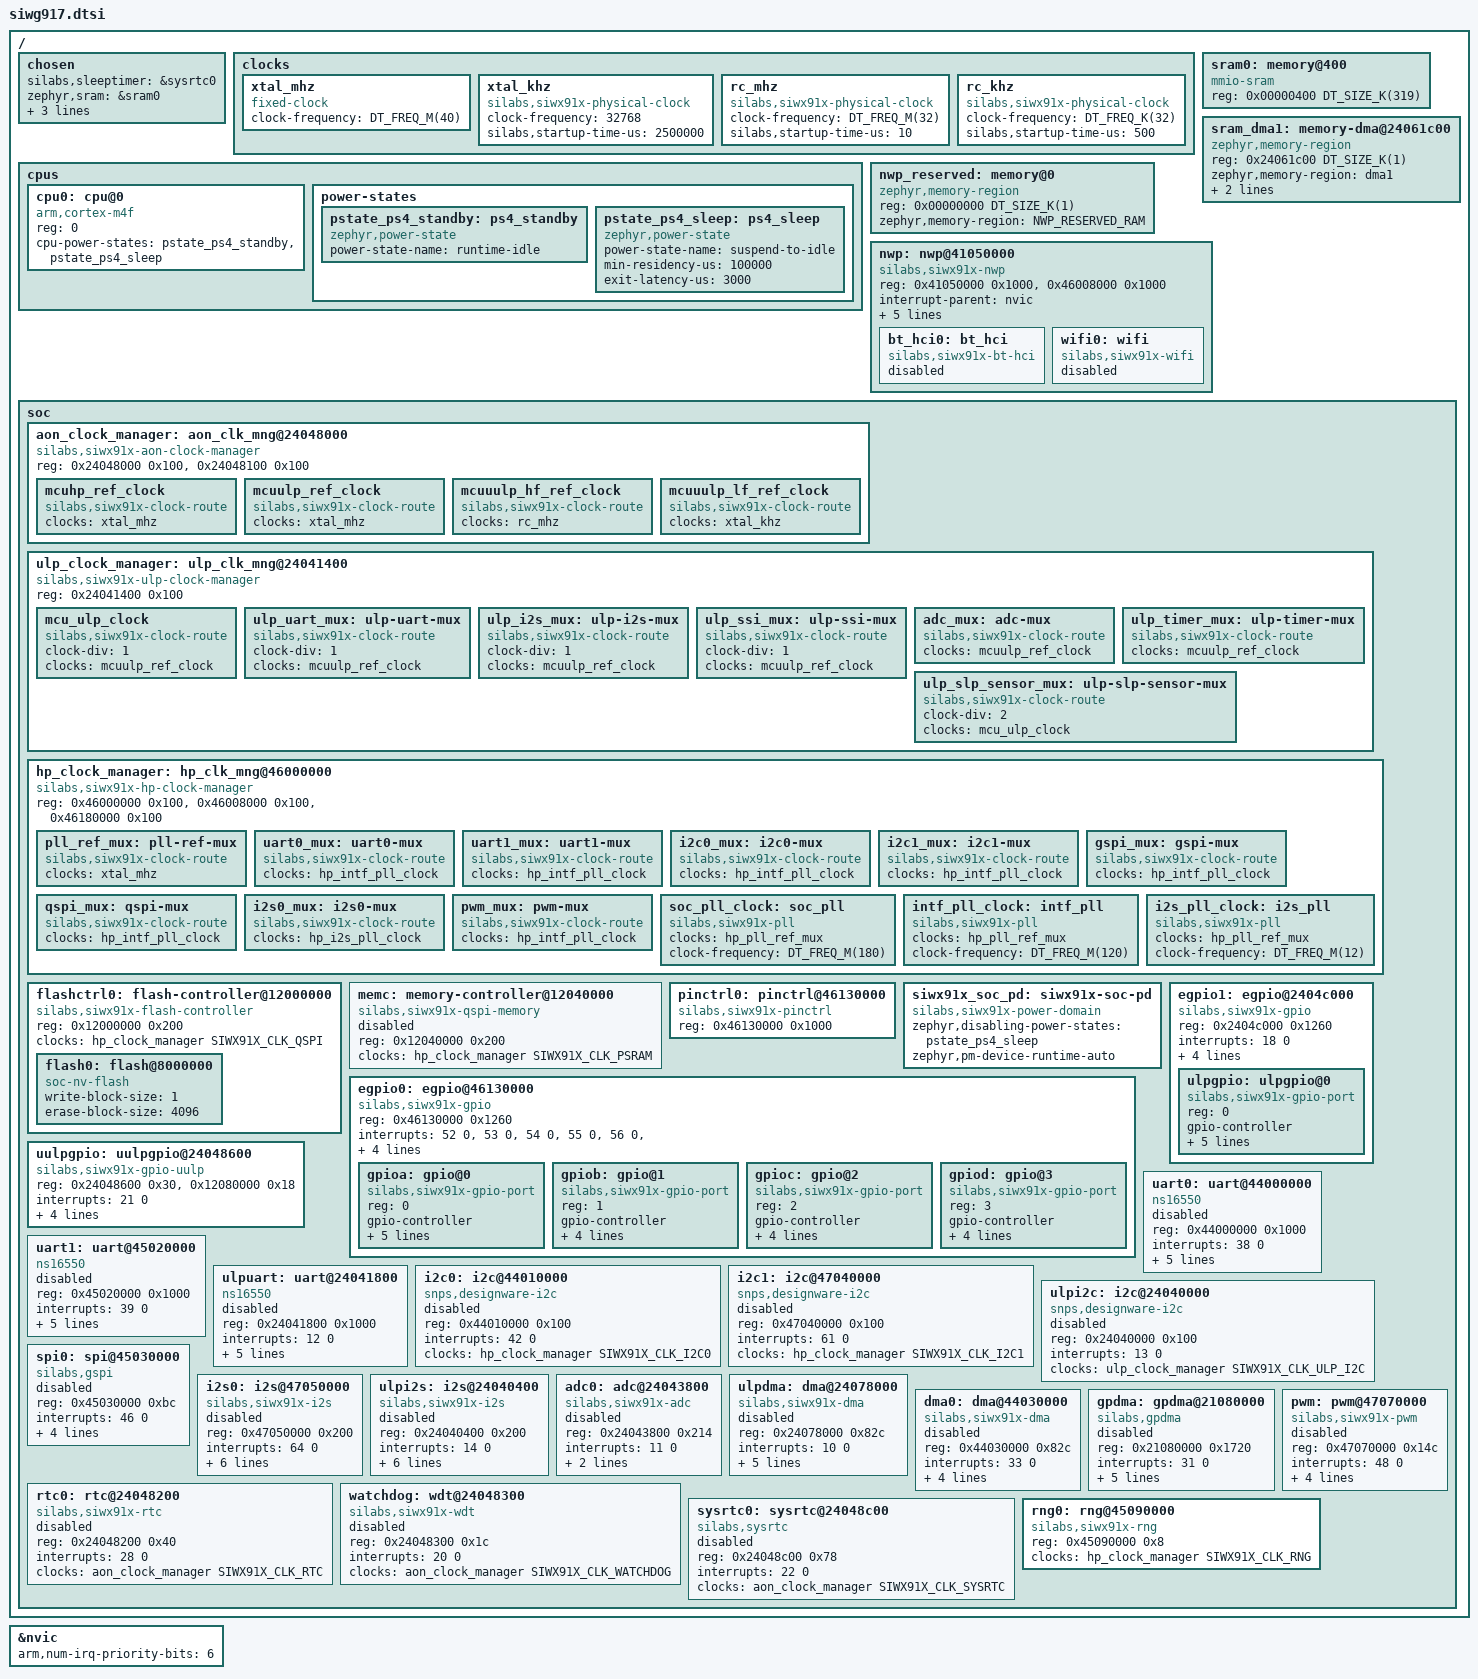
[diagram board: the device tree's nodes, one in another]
/*
 * Copyright (c) 2024-2025 Silicon Laboratories Inc.
 *
 * SPDX-License-Identifier: Apache-2.0
 */

#include <arm/armv7-m.dtsi>
#include <zephyr/dt-bindings/clock/silabs/siwx91x-clock.h>
#include <zephyr/dt-bindings/memory-attr/memory-attr-arm.h>
#include <freq.h>

/ {
	chosen {
		silabs,sleeptimer = &sysrtc0;
		zephyr,sram = &sram0;
		zephyr,entropy = &rng0;
		zephyr,flash = &flash0;
		zephyr,flash-controller = &flashctrl0;
	};

	clocks {

		xtal_mhz: xtal_mhz {
			compatible = "fixed-clock";
			#clock-cells = <0>;
			clock-frequency = <DT_FREQ_M(40)>;
			status = "okay";
		};

		xtal_khz: xtal_khz {
			compatible = "silabs,siwx91x-physical-clock";
			#clock-cells = <0>;
			clock-frequency = <32768>;
			silabs,startup-time-us = <2500000>;
			status = "okay";
		};

		rc_mhz: rc_mhz {
			compatible = "silabs,siwx91x-physical-clock";
			#clock-cells = <0>;
			clock-frequency = <DT_FREQ_M(32)>;
			silabs,startup-time-us = <10>;
			status = "okay";
		};

		rc_khz: rc_khz {
			compatible = "silabs,siwx91x-physical-clock";
			#clock-cells = <0>;
			clock-frequency = <DT_FREQ_K(32)>;
			silabs,startup-time-us = <500>;
			status = "okay";
		};

	};

	cpus {
		#address-cells = <1>;
		#size-cells = <0>;

		cpu0: cpu@0 {
			compatible = "arm,cortex-m4f";
			reg = <0>;
			cpu-power-states = <&pstate_ps4_standby &pstate_ps4_sleep>;
		};

		power-states {
			pstate_ps4_standby: ps4_standby {
				compatible = "zephyr,power-state";
				power-state-name = "runtime-idle";
			};

			pstate_ps4_sleep: ps4_sleep {
				compatible = "zephyr,power-state";
				power-state-name = "suspend-to-idle";
				min-residency-us = <100000>;
				exit-latency-us = <3000>;
			};
		};
	};

	/* First 1KB of SRAM reserved for NWP (protects against null pointers) */
	nwp_reserved: memory@0 {
		compatible = "zephyr,memory-region", "mmio-sram";
		reg = <0x00000000 DT_SIZE_K(1)>;
		zephyr,memory-region = "NWP_RESERVED_RAM";
	};

	/* Main SRAM for Cortex-M4 (shared with NWP)
	 * Configurable: 195KB, 255KB, or 319KB
	 * More to M4 = less to NWP (but better wireless performance)
	 */
	sram0: memory@400 {
		compatible = "mmio-sram";
		reg = <0x00000400 DT_SIZE_K(319)>;
	};

	/* DMA SRAM - No-cache memory for DMA transfers */
	sram_dma1: memory-dma@24061c00 {
		compatible = "zephyr,memory-region", "mmio-sram";
		reg = <0x24061c00 DT_SIZE_K(1)>;
		zephyr,memory-region = "dma1";
		zephyr,memory-attr = <DT_MEM_ARM(ATTR_MPU_RAM_NOCACHE)>;
	};

	nwp: nwp@41050000 {
		compatible = "silabs,siwx91x-nwp";
		reg = <0x41050000 0x1000>, <0x46008000 0x1000>;
		reg-names = "ta", "m4";
		interrupt-parent = <&nvic>;
		interrupts = <74 0>;
		interrupt-names = "nwp_irq";
		antenna-selection = "internal";
		support-1p8v;
		enable-xtal-correction;
		clock-frequency = <DT_FREQ_M(80)>;
		status = "okay";

		bt_hci0: bt_hci {
			compatible = "silabs,siwx91x-bt-hci";
			status = "disabled";
		};

		wifi0: wifi {
			compatible = "silabs,siwx91x-wifi";
			status = "disabled";
		};
	};

	soc {
		aon_clock_manager: aon_clk_mng@24048000 {
			compatible = "silabs,siwx91x-aon-clock-manager";
			reg = <0x24048000 0x100>,
			      <0x24048100 0x100>;

			reg-names = "mcu_aon","mcu_fsm";
			#clock-cells = <1>;
			status = "okay";

			mcuhp_ref_clock: mcuhp_ref_clock {
				compatible = "silabs,siwx91x-clock-route";
				#clock-cells = <0>;
				clocks = <&xtal_mhz>;
			};

			mcuulp_ref_clock: mcuulp_ref_clock {
				compatible = "silabs,siwx91x-clock-route";
				#clock-cells = <0>;
				clocks = <&xtal_mhz>;
			};

			/* Low-Power State machines clock */
			mcuuulp_hf_ref_clock: mcuuulp_hf_ref_clock {
				compatible = "silabs,siwx91x-clock-route";
				#clock-cells = <0>;
				clocks = <&rc_mhz>;
			};

			/* Shared clock for watchdog/Deep-sleep timer and GPIO timestamping in the UULP domain */
			mcuuulp_lf_ref_clock: mcuuulp_lf_ref_clock {
				compatible = "silabs,siwx91x-clock-route";
				#clock-cells = <0>;
				clocks = <&xtal_khz>;
			};

			/* RTC and watchdog LF muxes are fixed to UULP LF ref in hardware. */
			/* SYSRTC source: sleeptimer / HAL, not a clock-route child here. */
		};

		ulp_clock_manager: ulp_clk_mng@24041400 {
			compatible = "silabs,siwx91x-ulp-clock-manager";
			reg = <0x24041400 0x100>;
			reg-names = "ulpclk";
			#clock-cells = <1>;
			status = "okay";

			/* ULP AHB / processor interface clock (not owned by a single peripheral). */
			mcu_ulp_clock: mcu_ulp_clock {
				compatible = "silabs,siwx91x-clock-route";
				#clock-cells = <0>;
				clock-div = <1>;
				clocks = <&mcuulp_ref_clock>;
			};

			ulp_uart_mux: ulp-uart-mux {
				compatible = "silabs,siwx91x-clock-route";
				#clock-cells = <0>;
				clock-div = <1>;
				clocks = <&mcuulp_ref_clock>;
			};


			ulp_i2s_mux: ulp-i2s-mux {
				compatible = "silabs,siwx91x-clock-route";
				#clock-cells = <0>;
				clock-div = <1>;
				clocks = <&mcuulp_ref_clock>;
			};

			ulp_ssi_mux: ulp-ssi-mux {
				compatible = "silabs,siwx91x-clock-route";
				#clock-cells = <0>;
				clock-div = <1>;
				clocks = <&mcuulp_ref_clock>;
			};

			adc_mux: adc-mux {
				compatible = "silabs,siwx91x-clock-route";
				#clock-cells = <0>;
				clocks = <&mcuulp_ref_clock>;
			};

			ulp_timer_mux: ulp-timer-mux {
				compatible = "silabs,siwx91x-clock-route";
				#clock-cells = <0>;
				clocks = <&mcuulp_ref_clock>;
			};

			/* Sleep sensor clock - APB bus clock to configure uulp peripheral clocks */
			ulp_slp_sensor_mux: ulp-slp-sensor-mux {
				compatible = "silabs,siwx91x-clock-route";
				#clock-cells = <0>;
				clock-div = <2>;
				clocks = <&mcu_ulp_clock>;
			};

		};

		hp_clock_manager: hp_clk_mng@46000000 {
			compatible = "silabs,siwx91x-hp-clock-manager";
			reg = <0x46000000 0x100>,
			      <0x46008000 0x100>,
			      <0x46180000 0x100>;
			reg-names = "m4clk", "misc_config", "pll";
			#clock-cells = <1>;
			status = "okay";

			/* Shared PLL reference mux (one source for SoC/INTF/I2S PLLs). */
			pll_ref_mux: pll-ref-mux {
				compatible = "silabs,siwx91x-clock-route";
				#clock-cells = <0>;
				clocks = <&xtal_mhz>;
			};

			uart0_mux: uart0-mux {
				compatible = "silabs,siwx91x-clock-route";
				#clock-cells = <0>;
				clocks = <&hp_intf_pll_clock>;
			};

			uart1_mux: uart1-mux {
				compatible = "silabs,siwx91x-clock-route";
				#clock-cells = <0>;
				clocks = <&hp_intf_pll_clock>;
			};

			i2c0_mux: i2c0-mux {
				compatible = "silabs,siwx91x-clock-route";
				#clock-cells = <0>;
				clocks = <&hp_intf_pll_clock>;
			};

			i2c1_mux: i2c1-mux {
				compatible = "silabs,siwx91x-clock-route";
				#clock-cells = <0>;
				clocks = <&hp_intf_pll_clock>;
			};

			gspi_mux: gspi-mux {
				compatible = "silabs,siwx91x-clock-route";
				#clock-cells = <0>;
				clocks = <&hp_intf_pll_clock>;
			};

			qspi_mux: qspi-mux {
				compatible = "silabs,siwx91x-clock-route";
				#clock-cells = <0>;
				clocks = <&hp_intf_pll_clock>;
			};

			i2s0_mux: i2s0-mux {
				compatible = "silabs,siwx91x-clock-route";
				#clock-cells = <0>;
				clocks = <&hp_i2s_pll_clock>;
			};


			pwm_mux: pwm-mux {
				compatible = "silabs,siwx91x-clock-route";
				#clock-cells = <0>;
				clocks = <&hp_intf_pll_clock>;
			};

			soc_pll_clock: soc_pll {
				compatible = "silabs,siwx91x-pll";
				#clock-cells = <0>;
				clocks = <&hp_pll_ref_mux>;
				clock-frequency = <DT_FREQ_M(180)>;
			};

			intf_pll_clock: intf_pll {
				compatible = "silabs,siwx91x-pll";
				#clock-cells = <0>;
				clocks = <&hp_pll_ref_mux>;
				clock-frequency = <DT_FREQ_M(120)>;
			};

			i2s_pll_clock: i2s_pll {
				compatible = "silabs,siwx91x-pll";
				#clock-cells = <0>;
				clocks = <&hp_pll_ref_mux>;
				clock-frequency = <DT_FREQ_M(12)>;
			};
		};

		flashctrl0: flash-controller@12000000 {
			compatible = "silabs,siwx91x-flash-controller";
			reg = <0x12000000 0x200>;
			ranges;
			#address-cells = <1>;
			#size-cells = <1>;
			clocks = <&hp_clock_manager SIWX91X_CLK_QSPI>;

			flash0: flash@8000000 {
				compatible = "soc-nv-flash";
				write-block-size = <1>;
				erase-block-size = <4096>;
				#address-cells = <1>;
				#size-cells = <1>;
			};
		};

		memc: memory-controller@12040000 {
			compatible = "silabs,siwx91x-qspi-memory";
			reg = <0x12040000 0x200>;
			#address-cells = <1>;
			#size-cells = <1>;
			clocks = <&hp_clock_manager SIWX91X_CLK_PSRAM>;
			status = "disabled";
		};

		pinctrl0: pinctrl@46130000 {
			compatible = "silabs,siwx91x-pinctrl";
			reg = <0x46130000 0x1000>;
		};

		siwx91x_soc_pd: siwx91x-soc-pd {
			compatible = "silabs,siwx91x-power-domain";
			#power-domain-cells = <0>;
			zephyr,disabling-power-states = <&pstate_ps4_sleep>;
			zephyr,pm-device-runtime-auto;
			status = "okay";
		};

		egpio0: egpio@46130000 {
			compatible = "silabs,siwx91x-gpio";
			reg = <0x46130000 0x1260>;
			interrupts = <52 0>, <53 0>, <54 0>, <55 0>,
				     <56 0>, <57 0>, <58 0>, <59 0>;
			interrupt-names = "PIN0", "PIN1", "PIN2", "PIN3",
					  "PIN4", "PIN5", "PIN6", "PIN7";
			#address-cells = <1>;
			#size-cells = <0>;
			clocks = <&hp_clock_manager SIWX91X_CLK_GPIO>;
			power-domains = <&siwx91x_soc_pd>;
			zephyr,pm-device-runtime-auto;

			gpioa: gpio@0 {
				compatible = "silabs,siwx91x-gpio-port";
				reg = <0>;
				gpio-controller;
				#gpio-cells = <2>;
				ngpios = <16>;
				gpio-reserved-ranges = <0 6>;
				silabs,pads = [ff ff ff ff ff ff 01 02 03 04 05 06 07 ff ff 08];
				zephyr,pm-device-runtime-auto;
				status = "okay";
			};

			gpiob: gpio@1 {
				compatible = "silabs,siwx91x-gpio-port";
				reg = <1>;
				gpio-controller;
				#gpio-cells = <2>;
				ngpios = <16>;
				silabs,pads = [ff ff ff ff ff ff ff ff ff 00 00 00 00 00 00 09];
				zephyr,pm-device-runtime-auto;
				status = "okay";
			};

			gpioc: gpio@2 {
				compatible = "silabs,siwx91x-gpio-port";
				reg = <2>;
				gpio-controller;
				#gpio-cells = <2>;
				ngpios = <16>;
				silabs,pads = [09 09 09 ff ff ff ff ff ff ff ff ff ff ff 0a 0b];
				zephyr,pm-device-runtime-auto;
				status = "okay";
			};

			gpiod: gpio@3 {
				compatible = "silabs,siwx91x-gpio-port";
				reg = <3>;
				gpio-controller;
				#gpio-cells = <2>;
				ngpios = <10>;
				silabs,pads = [0c 0d 0e 0f 10 11 12 13 14 15 ff ff ff ff ff ff];
				zephyr,pm-device-runtime-auto;
				status = "okay";
			};
		};

		egpio1: egpio@2404c000 {
			compatible = "silabs,siwx91x-gpio";
			reg = <0x2404c000 0x1260>;
			interrupts = <18 0>;
			interrupt-names = "ULP";
			silabs,ulp;
			#address-cells = <1>;
			#size-cells = <0>;
			clocks = <&ulp_clock_manager SIWX91X_CLK_ULP_GPIO>;
			power-domains = <&siwx91x_soc_pd>;
			zephyr,pm-device-runtime-auto;

			ulpgpio: ulpgpio@0 {
				compatible = "silabs,siwx91x-gpio-port";
				reg = <0>;
				gpio-controller;
				#gpio-cells = <2>;
				ngpios = <12>;
				gpio-reserved-ranges = <3 1>;
				silabs,pads = [16 17 18 19 1a 1b 1c 1d 1e 1f 20 21 ff ff ff ff];
				zephyr,pm-device-runtime-auto;
				status = "okay";
			};
		};

		uulpgpio: uulpgpio@24048600 {
			compatible = "silabs,siwx91x-gpio-uulp";
			reg = <0x24048600 0x30>, <0x12080000 0x18>;
			reg-names = "ret", "int";
			interrupts = <21 0>;
			interrupt-names = "UULP";
			gpio-controller;
			#gpio-cells = <2>;
			ngpios = <4>;
			clocks = <&ulp_clock_manager SIWX91X_CLK_UULP_GPIO>;
			status = "okay";
		};

		uart0: uart@44000000 {
			compatible = "ns16550";
			reg = <0x44000000 0x1000>;
			interrupts = <38 0>;
			reg-shift = <2>;
			clocks = <&hp_clock_manager SIWX91X_CLK_UART0>;
			current-speed = <115200>;
			power-domains = <&siwx91x_soc_pd>;
			zephyr,pm-device-runtime-auto;
			status = "disabled";
		};

		uart1: uart@45020000 {
			compatible = "ns16550";
			reg = <0x45020000 0x1000>;
			interrupts = <39 0>;
			reg-shift = <2>;
			clocks = <&hp_clock_manager SIWX91X_CLK_UART1>;
			current-speed = <115200>;
			power-domains = <&siwx91x_soc_pd>;
			zephyr,pm-device-runtime-auto;
			status = "disabled";
		};

		ulpuart: uart@24041800 {
			compatible = "ns16550";
			reg = <0x24041800 0x1000>;
			interrupts = <12 0>;
			reg-shift = <2>;
			clocks = <&ulp_clock_manager SIWX91X_CLK_ULP_UART>;
			current-speed = <115200>;
			power-domains = <&siwx91x_soc_pd>;
			zephyr,pm-device-runtime-auto;
			status = "disabled";
		};

		i2c0: i2c@44010000 {
			compatible = "snps,designware-i2c";
			#address-cells = <1>;
			#size-cells = <0>;
			reg = <0x44010000 0x100>;
			interrupts = <42 0>;
			interrupt-names = "i2c0";
			clocks = <&hp_clock_manager SIWX91X_CLK_I2C0>;
			status = "disabled";
		};

		/* I2C 1 - HP domain */
		i2c1: i2c@47040000 {
			compatible = "snps,designware-i2c";
			#address-cells = <1>;
			#size-cells = <0>;
			reg = <0x47040000 0x100>;
			interrupts = <61 0>;
			interrupt-names = "i2c1";
			clocks = <&hp_clock_manager SIWX91X_CLK_I2C1>;
			status = "disabled";
		};
		/* I2C ULP - Ultra-low power domain */
		ulpi2c: i2c@24040000 {
			compatible = "snps,designware-i2c";
			#address-cells = <1>;
			#size-cells = <0>;
			reg = <0x24040000 0x100>;
			interrupts = <13 0>;
			interrupt-names = "i2c2";
			clocks = <&ulp_clock_manager SIWX91X_CLK_ULP_I2C>;
			status = "disabled";
		};

		/* SPI - HP domain */
		spi0: spi@45030000 {
			compatible = "silabs,gspi";
			#address-cells = <1>;
			#size-cells = <0>;
			reg = <0x45030000 0xbc>;
			interrupts = <46 0>;
			interrupt-names = "gspi";
			clocks = <&clock0 SIWX91X_CLK_GSPI>;
			dmas = <&gpdma 0 11>, <&gpdma 1 10>;
			dma-names = "tx", "rx";
			clocks = <&hp_clock_manager SIWX91X_CLK_GSPI>;
			power-domains = <&siwx91x_soc_pd>;
			zephyr,pm-device-runtime-auto;
			status = "disabled";
		};

		/* I2S HP - High Performance domain */
		i2s0: i2s@47050000 {
			compatible = "silabs,siwx91x-i2s";
			#address-cells = <1>;
			#size-cells = <0>;
			reg = <0x47050000 0x200>;
			interrupts = <64 0>;
			interrupt-names = "i2s0";
			silabs,channel-group = <0>;
			silabs,max-channel-count = <2>;
			clocks = <&hp_clock_manager SIWX91X_CLK_I2S0>,
				 <&hp_clock_manager SIWX91X_CLK_STATIC_I2S0>;
			power-domains = <&siwx91x_soc_pd>;
			zephyr,pm-device-runtime-auto;
			status = "disabled";
		};

		/* I2S ULP - Ultra-low power domain */
		ulpi2s: i2s@24040400 {
			compatible = "silabs,siwx91x-i2s";
			#address-cells = <1>;
			#size-cells = <0>;
			reg = <0x24040400 0x200>;
			interrupts = <14 0>;
			interrupt-names = "ulpi2s";
			silabs,channel-group = <0>;
			silabs,max-channel-count = <1>;
			clocks = <&ulp_clock_manager SIWX91X_CLK_ULP_I2S>,
				 <&ulp_clock_manager SIWX91X_CLK_STATIC_ULP_I2S>;
			power-domains = <&siwx91x_soc_pd>;
			zephyr,pm-device-runtime-auto;
			status = "disabled";
		};

		/* ADC - ULP domain */
		adc0: adc@24043800 {
			compatible = "silabs,siwx91x-adc";
			#address-cells = <1>;
			#size-cells = <0>;
			reg = <0x24043800 0x214>;
			interrupts = <11 0>;
			interrupt-names = "adc0";
			silabs,adc-sampling-rate = <100000>;
			clocks = <&ulp_clock_manager SIWX91X_CLK_ADC>;
			#io-channel-cells = <1>;
			status = "disabled";
		};

		/* ULP DMA - Ultra-low power domain */
		ulpdma: dma@24078000 {
			compatible = "silabs,siwx91x-dma";
			#address-cells = <1>;
			#size-cells = <0>;
			reg = <0x24078000 0x82c>;
			interrupts = <10 0>;
			interrupt-names = "ulpdma";
			clocks = <&ulp_clock_manager SIWX91X_CLK_ULP_DMA>;
			silabs,sram-region = <&sram_dma1>;
			#dma-cells = <1>;
			dma-channels = <12>;
			power-domains = <&siwx91x_soc_pd>;
			zephyr,pm-device-runtime-auto;
			status = "disabled";
		};

		/* DMA0 - HP domain */
		dma0: dma@44030000 {
			compatible = "silabs,siwx91x-dma";
			#address-cells = <1>;
			#size-cells = <0>;
			reg = <0x44030000 0x82c>;
			interrupts = <33 0>;
			interrupt-names = "dma0";
			clocks = <&hp_clock_manager SIWX91X_CLK_DMA0>;
			#dma-cells = <1>;
			dma-channels = <32>;
			power-domains = <&siwx91x_soc_pd>;
			zephyr,pm-device-runtime-auto;
			status = "disabled";
		};

		/* GPDMA - HP domain */
		gpdma: gpdma@21080000 {
			compatible = "silabs,gpdma";
			#address-cells = <1>;
			#size-cells = <0>;
			reg = <0x21080000 0x1720>;
			interrupts = <31 0>;
			interrupt-names = "gpdma";
			clocks = <&hp_clock_manager SIWX91X_CLK_GPDMA0>;
			silabs,channel-reg-base = <0x21081004>;
			silabs,dma-channel-count = <8>;
			#dma-cells = <2>;
			power-domains = <&siwx91x_soc_pd>;
			zephyr,pm-device-runtime-auto;
			status = "disabled";
		};

		pwm: pwm@47070000 {
			compatible = "silabs,siwx91x-pwm";
			#address-cells = <1>;
			#size-cells = <0>;
			reg = <0x47070000 0x14c>;
			interrupts = <48 0>;
			interrupt-names = "pwm";
			clocks = <&hp_clock_manager SIWX91X_CLK_PWM>;
			#pwm-cells = <2>;
			silabs,ch-prescaler = <64 64 64 64>;
			power-domains = <&siwx91x_soc_pd>;
			zephyr,pm-device-runtime-auto;
			status = "disabled";
		};

		rtc0: rtc@24048200 {
			compatible = "silabs,siwx91x-rtc";
			reg = <0x24048200 0x40>;
			interrupts = <28 0>;
			interrupt-names = "rtc";
			clocks = <&aon_clock_manager SIWX91X_CLK_RTC>;
			status = "disabled";
		};

		watchdog: wdt@24048300 {
			compatible = "silabs,siwx91x-wdt";
			#address-cells = <1>;
			#size-cells = <0>;
			reg = <0x24048300 0x1c>;
			interrupts = <20 0>;
			interrupt-names = "watchdog";
			clocks = <&aon_clock_manager SIWX91X_CLK_WATCHDOG>;
			status = "disabled";
		};

		sysrtc0: sysrtc@24048c00 {
			compatible = "silabs,sysrtc";
			reg = <0x24048c00 0x78>;
			interrupts = <22 0>;
			interrupt-names = "sysrtc";
			/* Only informative, managed by sleeptimer driver configuration file sl_sleeptimer_hal_si91x_sysrtc.c*/
			clocks = <&aon_clock_manager SIWX91X_CLK_SYSRTC>;
			status = "disabled";
		};

		rng0: rng@45090000 {
			compatible = "silabs,siwx91x-rng";
			reg = <0x45090000 0x8>;
			clocks = <&hp_clock_manager SIWX91X_CLK_RNG>;
		};
	};
};

&nvic {
	arm,num-irq-priority-bits = <6>;
};
